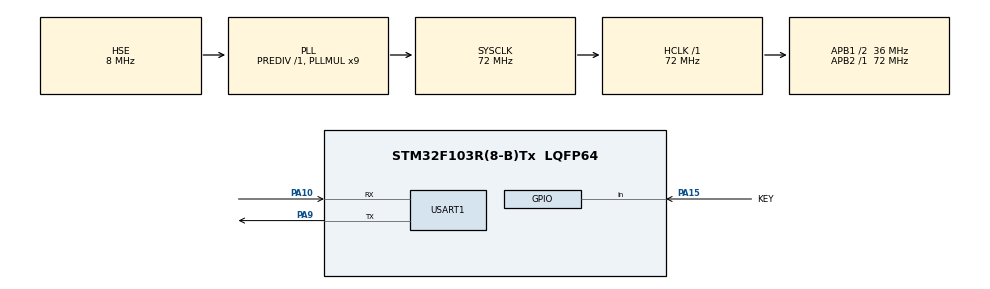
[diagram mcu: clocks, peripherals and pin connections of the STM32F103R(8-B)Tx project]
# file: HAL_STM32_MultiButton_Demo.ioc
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Mcu.Family=STM32F1
Mcu.Name=STM32F103R(8-B)Tx
Mcu.Package=LQFP64
NVIC.PriorityGroup=NVIC_PRIORITYGROUP_4
PA10.Mode=Asynchronous
PA10.Signal=USART1_RX
PA13.Mode=Serial_Wire
PA13.Signal=SYS_JTMS-SWDIO
PA14.Mode=Serial_Wire
PA14.Signal=SYS_JTCK-SWCLK
PA15.GPIO_Label=KEY
PA15.GPIO_PuPd=GPIO_PULLUP
PA15.Signal=GPIO_Input
PA9.Mode=Asynchronous
PA9.Signal=USART1_TX
PD0-OSC_IN.Mode=HSE-External-Oscillator
PD0-OSC_IN.Signal=RCC_OSC_IN
PD1-OSC_OUT.Mode=HSE-External-Oscillator
PD1-OSC_OUT.Signal=RCC_OSC_OUT
ProjectManager.HeapSize=0x0
ProjectManager.StackSize=0x400
ProjectManager.TargetToolchain=MDK-ARM V5
RCC.AHBFreq_Value=72000000
RCC.APB1CLKDivider=RCC_HCLK_DIV2
RCC.APB1Freq_Value=36000000
RCC.APB1TimFreq_Value=72000000
RCC.APB2Freq_Value=72000000
RCC.APB2TimFreq_Value=72000000
RCC.HCLKFreq_Value=72000000
RCC.PLLMUL=RCC_PLL_MUL9
RCC.PLLSourceVirtual=RCC_PLLSOURCE_HSE
RCC.SYSCLKFreq_VALUE=72000000
RCC.SYSCLKSource=RCC_SYSCLKSOURCE_PLLCLK
RCC.USBFreq_Value=72000000
USART1.VirtualMode=VM_ASYNC
board=custom

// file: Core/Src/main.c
/* USER CODE BEGIN Header */
/**
  ******************************************************************************
  * @file           : main.c
  * @brief          : Main program body
  ******************************************************************************
  * @attention
  *
  * <h2><center>&copy; Copyright (c) 2021 STMicroelectronics.
  * All rights reserved.</center></h2>
  *
  * This software component is licensed by ST under BSD 3-Clause license,
  * the "License"; You may not use this file except in compliance with the
  * License. You may obtain a copy of the License at:
  *                        opensource.org/licenses/BSD-3-Clause
  *
  ******************************************************************************
  */
/* USER CODE END Header */
#include "main.h"
#include "usart.h"
#include "gpio.h"

/* USER CODE BEGIN Includes */
#include "multi_button.h"
#include <stdio.h>
/* USER CODE END Includes */

void SystemClock_Config(void);

/* USER CODE BEGIN 0 */

struct Button button1;

/// 读取按键状态
uint8_t read_button_pin(void)
{
    return HAL_GPIO_ReadPin(KEY_GPIO_Port, KEY_Pin) == GPIO_PIN_SET ? 1 : 0;
}

/// 单击事件
void button_single_click_callback(void* arg)
{
	printf("%s\r\n", __FUNCTION__);
}

/// 双击事件
void button_double_click_callback(void* arg)
{
	printf("%s\r\n", __FUNCTION__);
}

/// 多次点击，如连续按3下
void button_press_repeat_callback(void* arg)
{
	struct Button* bt =  (struct Button *)arg;
	printf("%s:%d\r\n", __FUNCTION__, bt->repeat);  // repeat是变量用来记录按下的次数的
}

/// 长按触发
void button_press_start_callback(void* arg)
{
	printf("%s\r\n", __FUNCTION__);
}

/// 保持长按时一直触发
void button_press_hold_callback(void* arg)
{
	printf("%s\r\n", __FUNCTION__);
}

/// 按键弹起
void button_press_up_callback(void* arg)
{
	printf("%s\r\n", __FUNCTION__);
}

/// 按键按下
void button_press_down_callback(void* arg)
{
	printf("%s\r\n", __FUNCTION__);
}

int main(void)
{
    HAL_Init();
    SystemClock_Config();
    MX_GPIO_Init();
    MX_USART1_UART_Init();

	printf("############################ STM32 HAL MultiButton Demo ############################\r\n\r\n");

	// 初始化
    button_init(&button1, read_button_pin, 0);

	// 注册按键事件
    button_attach(&button1, SINGLE_CLICK, button_single_click_callback);
    button_attach(&button1, DOUBLE_CLICK, button_double_click_callback);
	button_attach(&button1, LONG_PRESS_START, button_press_start_callback);
	button_attach(&button1, LONG_PRESS_HOLD, button_press_hold_callback);
	button_attach(&button1, PRESS_REPEAT, button_press_repeat_callback);
	button_attach(&button1, PRESS_DOWN, button_press_down_callback);
	button_attach(&button1, PRESS_UP, button_press_up_callback);

	// 启动按键监测
	button_start(&button1);

    while (1)
    {
		button_ticks();             // 按键轮训，每TICKS_INTERVALms查询一次
		HAL_Delay(TICKS_INTERVAL);
    }
}

int fputc(int ch, FILE* fp)
{
	HAL_UART_Transmit(&huart1, (uint8_t *)&ch, 1, HAL_MAX_DELAY);
	return ch;
}

/* USER CODE END 0 */

int main2(void)
{

  /* MCU Configuration--------------------------------------------------------*/

  /* Reset of all peripherals, Initializes the Flash interface and the Systick. */
  HAL_Init();

  /* Configure the system clock */
  SystemClock_Config();

  /* Initialize all configured peripherals */
  MX_GPIO_Init();
  MX_USART1_UART_Init();

  /* Infinite loop */
    while (1)
    {

    }
}

void SystemClock_Config(void)
{
  RCC_OscInitTypeDef RCC_OscInitStruct = {0};
  RCC_ClkInitTypeDef RCC_ClkInitStruct = {0};

  /** Initializes the RCC Oscillators according to the specified parameters
  * in the RCC_OscInitTypeDef structure.
  */
  RCC_OscInitStruct.OscillatorType = RCC_OSCILLATORTYPE_HSE;
  RCC_OscInitStruct.HSEState = RCC_HSE_ON;
  RCC_OscInitStruct.HSEPredivValue = RCC_HSE_PREDIV_DIV1;
  RCC_OscInitStruct.HSIState = RCC_HSI_ON;
  RCC_OscInitStruct.PLL.PLLState = RCC_PLL_ON;
  RCC_OscInitStruct.PLL.PLLSource = RCC_PLLSOURCE_HSE;
  RCC_OscInitStruct.PLL.PLLMUL = RCC_PLL_MUL9;
  if (HAL_RCC_OscConfig(&RCC_OscInitStruct) != HAL_OK)
  {
    Error_Handler();
  }
  /** Initializes the CPU, AHB and APB buses clocks
  */
  RCC_ClkInitStruct.ClockType = RCC_CLOCKTYPE_HCLK|RCC_CLOCKTYPE_SYSCLK
                              |RCC_CLOCKTYPE_PCLK1|RCC_CLOCKTYPE_PCLK2;
  RCC_ClkInitStruct.SYSCLKSource = RCC_SYSCLKSOURCE_PLLCLK;
  RCC_ClkInitStruct.AHBCLKDivider = RCC_SYSCLK_DIV1;
  RCC_ClkInitStruct.APB1CLKDivider = RCC_HCLK_DIV2;
  RCC_ClkInitStruct.APB2CLKDivider = RCC_HCLK_DIV1;

  if (HAL_RCC_ClockConfig(&RCC_ClkInitStruct, FLASH_LATENCY_2) != HAL_OK)
  {
    Error_Handler();
  }
}

void Error_Handler(void)
{
    __disable_irq();
    while (1)
    {
    }
}

/************************ (C) COPYRIGHT STMicroelectronics *****END OF FILE****/
